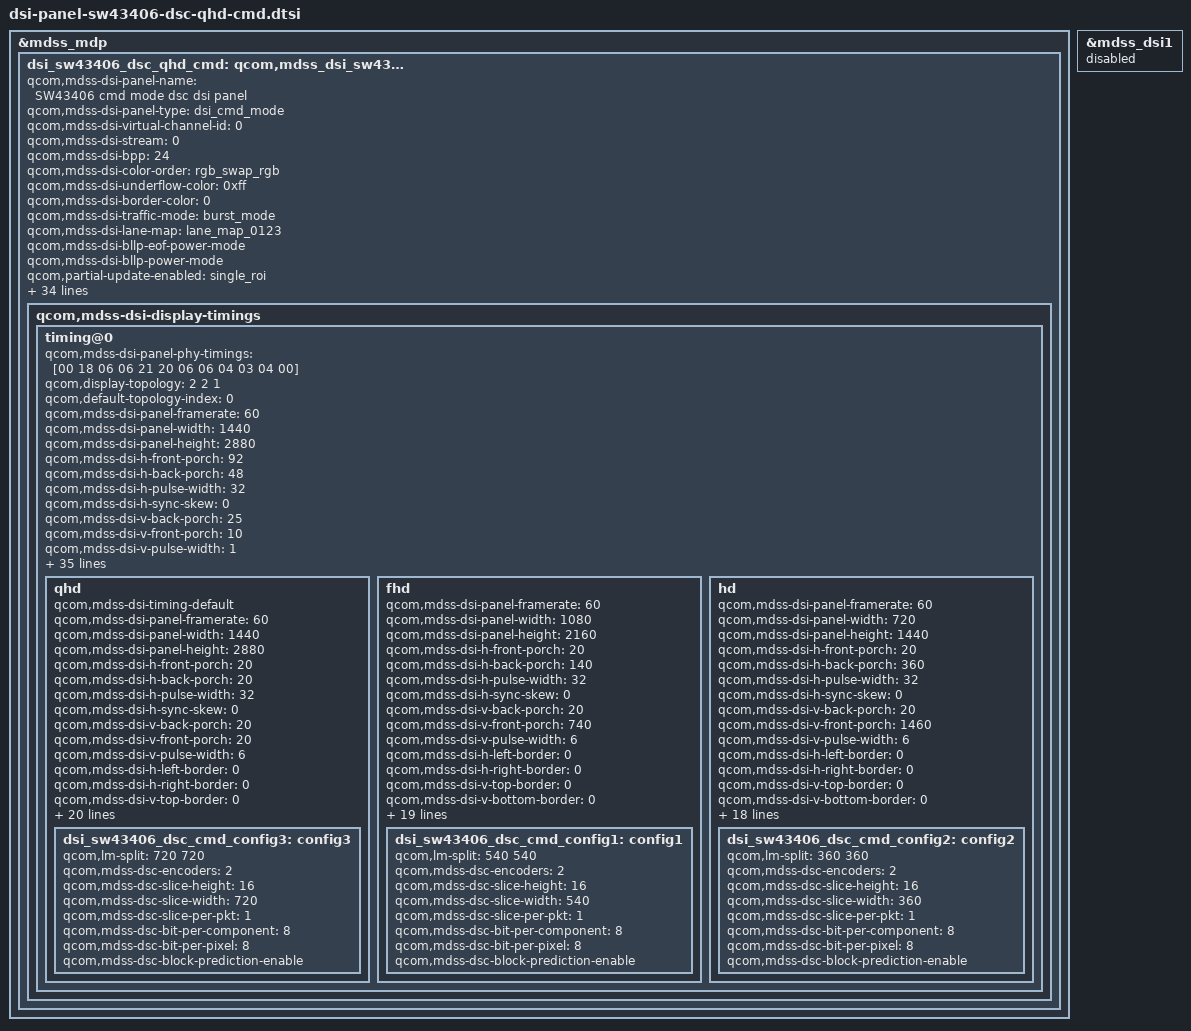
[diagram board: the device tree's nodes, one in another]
/* Copyright (c) 2014, Code Aurora Forum. All rights reserved.
 *
 * This program is free software; you can redistribute it and/or modify
 * it under the terms of the GNU General Public License version 2 and
 * only version 2 as published by the Free Software Foundation.
 *
 * This program is distributed in the hope that it will be useful,
 * but WITHOUT ANY WARRANTY; without even the implied warranty of
 * MERCHANTABILITY or FITNESS FOR A PARTICULAR PURPOSE.  See the
 * GNU General Public License for more details.
 */

//#include "dsi-panel-sw43406-dynamic-resolution-switching.dtsi"

&mdss_mdp {
    dsi_sw43406_dsc_qhd_cmd: qcom,mdss_dsi_sw43406_dsc_qhd_cmd {
        qcom,mdss-dsi-panel-name = "SW43406 cmd mode dsc dsi panel";
		qcom,mdss-dsi-panel-type = "dsi_cmd_mode";

		qcom,mdss-dsi-virtual-channel-id = <0>;
		qcom,mdss-dsi-stream = <0>;
		qcom,mdss-dsi-bpp = <24>;
		qcom,mdss-dsi-color-order = "rgb_swap_rgb";
		qcom,mdss-dsi-underflow-color = <0xff>;
		qcom,mdss-dsi-border-color = <0>;
		//qcom,esd-check-enabled;
		//qcom,mdss-dsi-panel-status-check-mode = "te_signal_check";
		qcom,mdss-dsi-traffic-mode = "burst_mode";
		qcom,mdss-dsi-lane-map = "lane_map_0123";
		qcom,mdss-dsi-bllp-eof-power-mode;
		qcom,mdss-dsi-bllp-power-mode;
		qcom,partial-update-enabled = "single_roi";
		qcom,panel-roi-alignment = <1440 16 1440 16 1440 16>;
		qcom,mdss-dsi-lane-0-state;
		qcom,mdss-dsi-lane-1-state;
		qcom,mdss-dsi-lane-2-state;
		qcom,mdss-dsi-lane-3-state;
		qcom,mdss-dsi-reset-sequence = <1 10>, <0 2>, <1 10>;
		qcom,mdss-dsi-dma-trigger = "trigger_sw";
		qcom,mdss-dsi-mdp-trigger = "none";
		qcom,mdss-dsi-te-pin-select = <1>;
		qcom,mdss-dsi-wr-mem-start = <0x2c>;
		qcom,mdss-dsi-wr-mem-continue = <0x3c>;
		qcom,mdss-dsi-te-dcs-command = <1>;
		qcom,mdss-dsi-te-check-enable;
		qcom,mdss-dsi-te-using-te-pin;
		qcom,mdss-dsi-lp11-init;
//		qcom,mdss-dsi-tx-eot-append;
		qcom,mdss-mdp-transfer-time-us = <15000>;
//		qcom,ulps-enabled;
		qcom,mdss-dsi-force-clock-lane-hs = <1>;

		qcom,mdss-dsi-panel-hdr-enabled;
		qcom,mdss-dsi-panel-hdr-color-primaries = <14880 15935 32435 16555 14945 30910 7790 3415>;
		qcom,mdss-dsi-panel-peak-brightness = <5643000>;		/* max. 500nits */
		qcom,mdss-dsi-panel-blackness-level = <6134>;
		qcom,dynamic-mode-switch-enabled;
		qcom,dynamic-mode-switch-type = "dynamic-resolution-switch-immediate";

		lge,blmap = <
			3
			30 30 30 30 30 30 30 30 30 30 30 30 30 30 30 30 30 30 31 33
			35 35 36 37 38 39 39 40 41 41 42 42 42 43 44 45 45 45 45 45
			46 47 48 48 48 48 48 49 49 50 51 51 51 51 52 53 53 54 55 55
			55 55 56 56 57 57 57 58 59 60 60 60 61 61 62 62 63 64 65 66
			67 68 69 69 70 71 73 73 74 75 76 77 78 79 80 81 82 82 83 84
			85 86 87 88 89 90 91 92 92 92 93 94 96 98 98 99 100 102 104 105
			106 107 108 109 110 111 112 113 114 114 114 115 116 117 118 120 120 120 121 122
			123 123 123 124 124 125 126 127 128 128 129 130 131 132 133 134 135 135 135 136
			137 138 139 139 140 141 142 143 143 143 144 145 146 147 148 149 150 151 152 153
			153 153 154 155 156 156 157 158 159 160 160 161 162 162 163 164 165 166 167 169
			169 171 173 175 177 179 179 179 180 181 183 185 185 186 187 188 190 191 192 193
			195 196 197 198 199 200 201 202 203 205 206 208 209 210 211 212 213 214 215 216
			217 218 219 221 222 224 226 227 229 230 232 234 236 238 239 239 239 239 239 239
			239 239 239 239 239 239 239 240 240 240 240 240 240 240 240 240 240 240 240 240
			240 240 240 240 240 240 240 240 240 240 240 240 240 240 240 240 241 241 241 241
			241 241 241 241 241 241 241 241 241 241 241 241 242 242 242 242 242 242 242 242
			242 242 242 242 242 242 243 243 243 243 243 243 243 243 243 244 244 244 244 245
			245 245 245 246 246 246 246 246 247 247 247 247 248 248 248 248 249 249 249 249
			250 250 250 250 251 251 251 251 251 251 251 251 251 251 251 251 251 251 251 251
			251 251 251 251 251 251 251 251 251 251 251 251 251 251 251 251 251 251 251 251
			251 251 251 251 251 251 251 251 251 251 251 251 251 251 251 251 251 251 251 251
			251 251 251 251 251 251 251 251 251 251 251 251 251 251 251 251 251 251 251 251
			251 251 251 251 251 251 251 251 251 251 251 251 251 251 251 251 251 251 251 251
			251 251 251 251 251 251 251 251 251 251 251 251 251 251 251 251 251 251 251 251
			251 251 251 251 251 251 251 251 251 251 251 251 251 251 251 251 251 251 251 251
			251 251 251 251 251 251 251 251 251 251 251
		>;

		lge,blmap-ex = <
			3
			41 41 41 41 41 41 41 41 41 41 41 41 41 41 41 42 42 42 43 43
			44 44 45 46 47 49 49 49 50 51 53 54 55 56 58 60 61 63 64 65
			67 68 70 71 72 74 76 78 79 81 83 84 86 87 89 91 93 95 97 99
			100 101 103 104 106 107 108 110 113 116 117 119 121 123 125 126 127 129 131 134
			135 136 138 140 142 144 146 147 148 150 152 155 157 159 162 164 166 167 169 171
			173 176 177 178 179 181 183 185 187 189	191 193 195 198 200 202 204 206 209 210
			212 214 216 219 220 222 224 226 228 230	232 234 236 238 240 243 244 245 246 249
			252 252 253 254 254 255 255 255 255 255	255 255 255 255 255 255 255 255 255 255
			255 255 255 255 255 255 255 255 255 255	255 255 255 255 255 255 255 255 255 255
			255 255 255 255 255 255 255 255 255 255	255 255 255 255 255 255 255 255 255 255
			255 255 255 255 255 255 255 255 255 255	255 255 255 255 255 255 255 255 255 255
			255 255 255 255 255 255 255 255 255 255	255 255 255 255 255 255 255 255 255 255
			255 255 255 255 255 255 255 255 255 255	255 255 255 255 255 255 255 255 255 255
			255 255 255 255 255 255 255 255 255 255	255 255 255 255 255 255 255 255 255 255
			255 255 255 255 255 255 255 255 255 255	255 255 255 255 255 255 255 255 255 255
			255 255 255 255 255 255 255 255 255 255	255 255 255 255 255 255 255 255 255 255
			255 255 255 255 255 255 255 255 255 255	255 255 255 255 255 255 255 255 255 255
			255 255 255 255 255 255 255 255 255 255	255 255 255 255 255 255 255 255 255 255
			255 255 255 255 255 255 255 255 255 255	255 255 255 255 255 255 255 255 255 255
			255 255 255 255 255 255 255 255 255 255	255 255 255 255 255 255 255 255 255 255
			255 255 255 255 255 255 255 255 255 255	255 255 255 255 255 255 255 255 255 255
			255 255 255 255 255 255 255 255 255 255	255 255 255 255 255 255 255 255 255 255
			255 255 255 255 255 255 255 255 255 255	255 255 255 255 255 255 255 255 255 255
			255 255 255 255 255 255 255 255 255 255	255 255 255 255 255 255 255 255 255 255
			255 255 255 255 255 255 255 255 255 255	255 255 255 255 255 255 255 255 255 255
			255 255 255 255 255 255 255 255 255 255	255
		>;

		qcom,mdss-pan-physical-width-dimension = <68>;
		qcom,mdss-pan-physical-height-dimension = <136>;

		qcom,mdss-dsi-t-clk-post = <0x0C>;
		qcom,mdss-dsi-t-clk-pre = <0x27>;

		qcom,mdss-dsi-display-timings {
			timing@0{
				qcom,mdss-dsi-panel-phy-timings = [00 18 06 06 21 20 06 06 04 03 04 00];
				qcom,display-topology = <2 2 1>;
				qcom,default-topology-index = <0>;
				qcom,mdss-dsi-panel-framerate = <60>;
				qcom,mdss-dsi-panel-width = <1440>;
				qcom,mdss-dsi-panel-height = <2880>;
				qcom,mdss-dsi-h-front-porch = <92>;
				qcom,mdss-dsi-h-back-porch = <48>;
				qcom,mdss-dsi-h-pulse-width = <32>;
				qcom,mdss-dsi-h-sync-skew = <0>;
				qcom,mdss-dsi-v-back-porch = <25>;
				qcom,mdss-dsi-v-front-porch = <10>;
				qcom,mdss-dsi-v-pulse-width = <1>;
				qcom,mdss-dsi-h-left-border = <0>;
				qcom,mdss-dsi-h-right-border = <0>;
				qcom,mdss-dsi-v-top-border = <0>;
				qcom,mdss-dsi-v-bottom-border = <0>;
				qcom,mdss-dsi-on-command = [
					39 01 00 00 00 00 03 B0 60 43
					15 01 00 00 00 00 02 3D 00
					39 01 00 00 00 00 03 DF 0B 00
					15 01 00 00 00 00 02 F2 00
					39 01 00 00 01 00 03 FF 03 00
					05 01 00 00 14 00 01 35
					05 01 00 00 14 00 01 11
					15 01 00 00 00 00 02 51 4F
					15 01 00 00 00 00 02 53 00
					15 01 00 00 00 00 02 55 0C
					39 01 00 00 00 00 03 B0 A5 00
					39 01 00 00 00 00 16 D4 10 00 FF A8 80 54 80 20 20 20 20 56 00 56 00 56 00 15 55 56 55
					39 01 00 00 00 00 1D D6 70 56 5E 40 18 18 F0 C8 88 88 DC 00 10 06 10 30 78 78 78 6C 74 5C 34 52 64 60 58 5C
					39 01 00 00 00 00 1D D7 70 5A 58 48 38 08 D8 E8 06 F8 F8 E8 A4 D8 28 3E 7C 74 6C 64 68 60 64 64 74 50 48 5A
					39 01 00 00 00 00 1D D8 70 48 50 38 30 14 F0 C8 84 82 C0 1C 14 00 00 3A 6A 62 54 50 58 4C 28 44 62 5A 48 52
					39 01 00 00 00 00 1D D9 70 5A 5E 40 30 08 F4 F8 00 EC F0 FD 14 06 3C 3A 6A 64 5C 5C 62 62 50 56 60 52 50 56
					39 01 00 00 00 00 03 FB 03 77
					39 01 00 00 14 00 06 ED 13 00 07 00 31
					39 01 00 00 3C 00 03 B0 A5 00
					];
				qcom,mdss-dsi-on-command-state = "dsi_lp_mode";

				qcom,mdss-dsi-post-panel-on-command = [
					39 01 00 00 3C 00 03 B0 A5 00
					39 01 00 00 00 00 03 B2 5D 01
					05 01 00 00 00 00 01 29
					];

				qcom,mdss-dsi-off-command = [
					39 01 00 00 00 00 05 E8 08 98 18 05
					05 01 00 00 00 00 01 28
					05 01 00 00 96 00 01 10
					];
				qcom,mdss-dsi-off-command-state = "dsi_lp_mode";

				/* lge,mode-change-cmds-doze-suspend-to-panel-on-low-power  */
				lge,mdss-change-cmds-doze-suspend-to-panel-on-low-power = [
					39 01 00 00 00 00 08 CA 00 46 00 46 00 16 11
					39 01 00 00 00 00 1F CB 02 D8 00 02 D8 00 02 D8 00 02 D8 00 02 D8 00 02 D8 00 02 D8 00 02 D8 00 02 D8 00 02 D8 00
					39 01 00 00 00 00 13 CC 02 D8 00 02 D8 00 02 D8 00 0B 5E 00 0B 5E 00 55 12 13
					39 01 00 00 28 00 0F E2 20 0D 08 A8 0A AA 04 A4 80 80 80 5C 5C 5C
					05 01 00 00 00 00 01 34
					05 01 00 00 00 00 01 38
					15 01 00 00 00 00 02 31 00
					15 01 00 00 00 00 02 51 03
					15 01 00 00 00 00 02 5E 00
					05 01 00 00 55 00 01 13
					05 01 00 00 00 00 01 35
					39 01 00 00 00 00 08 CA 00 46 00 46 00 16 11
					39 01 00 00 00 00 1F CB 20 01 CC 20 01 CC 20 01 CC 11 23 AB 11 23 AB 01 D9 F5 01 D9 F5 02 79 55 02 79 55 02 B3 1A
					39 01 00 00 00 00 13 CC 20 01 CC 20 6D 60 11 23 AB 29 18 1E 29 18 1E 55 12 13
				];
				/* lge,mode-change-cmds-panel-on-to-doze-suspend-low-power */
				lge,mdss-change-cmds-panel-on-to-doze-suspend-low-power = [
					39 01 00 00 00 00 03 B0 A5 00
					39 01 00 00 00 00 0A D2 1A BC 02 BC 01 00 06 FF 00
					39 01 00 00 00 00 08 CA 00 46 00 46 00 16 11
					39 01 00 00 00 00 1F CB 02 D8 00 02 D8 00 02 D8 00 02 D8 00 02 D8 00 02 D8 00 02 D8 00 02 D8 00 02 D8 00 02 D8 00
					39 01 00 00 00 00 13 CC 02 D8 00 02 D8 00 02 D8 00 0B 5E 00 0B 5E 00 55 12 13
					39 01 00 00 00 00 09 E5 04 04 03 03 56 21 33 0A
					39 01 00 00 00 00 13 E7 00 0D 76 1A 00 00 0D 44 0D 76 0D 0D 00 0D 0D 0D 4A 00
					39 01 00 00 46 00 0F E2 20 03 08 A8 0A AA 04 A4 80 80 80 5C 5C 5C
					05 01 00 00 00 00 01 34
					39 01 00 00 00 00 05 30 00 00 0B 3F
					15 01 00 00 00 00 02 31 00
					15 01 00 00 00 00 02 5E 00
					05 01 00 00 00 00 01 12
					39 01 00 00 00 00 0B E0 18 10 11 00 00 20 00 00 20 20
					05 01 00 00 55 00 01 39
					05 01 00 00 00 00 01 35
					39 01 00 00 00 00 08 CA 00 46 00 46 00 16 11
					39 01 00 00 00 00 1F CB 20 01 CC 20 01 CC 20 01 CC 11 23 AB 11 23 AB 01 D9 F5 01 D9 F5 02 79 55 02 79 55 02 B3 1A
					39 01 00 00 00 00 13 CC 20 01 CC 20 6D 60 11 23 AB 29 18 1E 29 18 1E 55 12 13
				];
				lge,mdss-change-cmds-doze-suspend-to-panel-on-state = "dsi_lp_mode";
				lge,mdss-change-cmds-panel-on-to-doze-suspend-state = "dsi_lp_mode";

				lge,mdss-ddvdh-default-command = [
					/* Positive Gamma Curve for Red */
					39 01 00 00 00 00 0E D0 00 10 20 2F 3B 43 4E 44 37 28 17 06 03
					/* Negative Gamma Curve for Red */
					39 01 00 00 00 00 0E D1 00 10 20 2B 38 41 4C 44 37 28 17 00 03
				];

				lge,mdss-ddvdh-tuning-command = [
					/* Positive Gamma Curve for Red */
					39 01 00 00 00 00 0E D0 00 30 40 48 4F 55 3B 31 24 17 08 00 03
					/* Negative Gamma Curve for Red */
					39 01 00 00 00 00 0E D1 00 30 40 48 4F 55 3B 31 24 17 08 00 03
				];
				lge,mdss-ddvdh-default-state = "dsi_lp_mode";
				lge,mdss-ddvdh-tuning-state = "dsi_lp_mode";
				qcom,mode-control-dsi-state = "dsi_lp_mode";

				qcom,mdss-dsi-h-sync-pulse = <0>;
				qcom,compression-mode = "dsc";
				qcom,mdss-dsc-slice-height = <16>;
				qcom,mdss-dsc-slice-width = <720>;
				qcom,mdss-dsc-slice-per-pkt = <2>;
				qcom,mdss-dsc-bit-per-component = <8>;
				qcom,mdss-dsc-bit-per-pixel = <8>;
				qcom,mdss-dsc-block-prediction-enable;

				qhd {
					qcom,mdss-dsi-timing-default;
					qcom,mdss-dsi-panel-framerate = <60>;
					qcom,mdss-dsi-panel-width = <1440>;
					qcom,mdss-dsi-panel-height = <2880>;
					qcom,mdss-dsi-h-front-porch = <20>;
					qcom,mdss-dsi-h-back-porch = <20>;
					qcom,mdss-dsi-h-pulse-width = <32>;
					qcom,mdss-dsi-h-sync-skew = <0>;
					qcom,mdss-dsi-v-back-porch = <20>;
					qcom,mdss-dsi-v-front-porch = <20>;
					qcom,mdss-dsi-v-pulse-width = <6>;
					qcom,mdss-dsi-h-left-border = <0>;
					qcom,mdss-dsi-h-right-border = <0>;
					qcom,mdss-dsi-v-top-border = <0>;
					qcom,mdss-dsi-v-bottom-border = <0>;
					qcom,mdss-dsi-panel-timings = [00 14 05 05 08 0E 04 05 04 03 04 00];
					qcom,mdss-dsi-t-clk-post = <0x06>;
					qcom,mdss-dsi-t-clk-pre = <0x20>;

					qcom,mdss-dsi-on-command = [
						39 01 00 00 00 00 03 B0 20 43
						39 01 00 00 00 00 02 3D 00
						39 01 00 00 00 00 03 DF 0B 00
						39 01 00 00 00 00 02 F2 00
						39 01 00 00 00 00 03 FF 03 00
						05 01 00 00 78 00 01 11
						05 01 00 00 00 00 01 29
						39 01 00 00 01 00 03 B0 A5 43
						];
					qcom,mdss-dsi-on-command-state = "dsi_lp_mode";
					qcom,mdss-dsi-off-command = [
						05 01 00 00 00 00 01 28
						05 01 00 00 5A 00 01 10
						];
					qcom,mdss-dsi-timing-switch-command = [
						15 01 00 00 00 00 03 B0 20 43
						39 01 00 00 00 00 02 3D 00
						];
					qcom,mdss-dsi-timing-switch-command-state = "dsi_lp_mode";

					qcom,mdss-dsi-off-command-state = "dsi_lp_mode";
					qcom,compression-mode = "dsc";
					qcom,config-select = <&dsi_sw43406_dsc_cmd_config3>;
					qcom,mdss-dsc-version = <0x11>;
					qcom,mdss-dsc-scr-version = <0x1>;

					dsi_sw43406_dsc_cmd_config3: config3 {
				     		qcom,lm-split = <720 720>;
				     		qcom,mdss-dsc-encoders = <2>;
				     		qcom,mdss-dsc-slice-height = <16>;
				     		qcom,mdss-dsc-slice-width = <720>;
				     		qcom,mdss-dsc-slice-per-pkt = <1>;

						qcom,mdss-dsc-bit-per-component = <8>;
						qcom,mdss-dsc-bit-per-pixel = <8>;
						qcom,mdss-dsc-block-prediction-enable;
					};
				};

				fhd {
					qcom,mdss-dsi-panel-framerate = <60>;
					qcom,mdss-dsi-panel-width = <1080>;
					qcom,mdss-dsi-panel-height = <2160>;
					qcom,mdss-dsi-h-front-porch = <20>;
					qcom,mdss-dsi-h-back-porch = <140>;
					qcom,mdss-dsi-h-pulse-width = <32>;
					qcom,mdss-dsi-h-sync-skew = <0>;
					qcom,mdss-dsi-v-back-porch = <20>;
					qcom,mdss-dsi-v-front-porch = <740>;
					qcom,mdss-dsi-v-pulse-width = <6>;
					qcom,mdss-dsi-h-left-border = <0>;
					qcom,mdss-dsi-h-right-border = <0>;
					qcom,mdss-dsi-v-top-border = <0>;
					qcom,mdss-dsi-v-bottom-border = <0>;
					qcom,mdss-dsi-panel-timings = [00 14 05 05 08 0E 04 05 04 03 04 00];
					qcom,mdss-dsi-t-clk-post = <0x06>;
					qcom,mdss-dsi-t-clk-pre = <0x20>;

					qcom,mdss-dsi-on-command = [
						39 01 00 00 00 00 03 B0 20 43
						39 01 00 00 00 00 02 3D 01
						39 01 00 00 00 00 03 DF 0B 00
						39 01 00 00 00 00 02 F2 00
						39 01 00 00 00 00 03 FF 03 00
						05 01 00 00 78 00 01 11
						05 01 00 00 00 00 01 29
						39 01 00 00 01 00 03 B0 A5 43
						];
					qcom,mdss-dsi-on-command-state = "dsi_lp_mode";
					qcom,mdss-dsi-off-command = [
						05 01 00 00 00 00 01 28
						05 01 00 00 5A 00 01 10
						];
					qcom,mdss-dsi-timing-switch-command = [
						15 01 00 00 00 00 03 B0 20 43
						39 01 00 00 00 00 02 3D 01
						];
					qcom,mdss-dsi-timing-switch-command-state = "dsi_lp_mode";

					qcom,mdss-dsi-off-command-state = "dsi_lp_mode";
					qcom,compression-mode = "dsc";
					qcom,config-select = <&dsi_sw43406_dsc_cmd_config1>;
					qcom,mdss-dsc-version = <0x11>;
					qcom,mdss-dsc-scr-version = <0x1>;
					dsi_sw43406_dsc_cmd_config1: config1 {
				     		qcom,lm-split = <540 540>;

				     		qcom,mdss-dsc-encoders = <2>;
				     		qcom,mdss-dsc-slice-height = <16>;
				     		qcom,mdss-dsc-slice-width = <540>;
				     		qcom,mdss-dsc-slice-per-pkt = <1>;

				     		qcom,mdss-dsc-bit-per-component = <8>;
				     		qcom,mdss-dsc-bit-per-pixel = <8>;
				     		qcom,mdss-dsc-block-prediction-enable;
					};
				};

				hd {
					qcom,mdss-dsi-panel-framerate = <60>;
					qcom,mdss-dsi-panel-width = <720>;
					qcom,mdss-dsi-panel-height = <1440>;
					qcom,mdss-dsi-h-front-porch = <20>;
					qcom,mdss-dsi-h-back-porch = <360>;
					qcom,mdss-dsi-h-pulse-width = <32>;
					qcom,mdss-dsi-h-sync-skew = <0>;
					qcom,mdss-dsi-v-back-porch = <20>;
					qcom,mdss-dsi-v-front-porch = <1460>;
					qcom,mdss-dsi-v-pulse-width = <6>;
					qcom,mdss-dsi-h-left-border = <0>;
					qcom,mdss-dsi-h-right-border = <0>;
					qcom,mdss-dsi-v-top-border = <0>;
					qcom,mdss-dsi-v-bottom-border = <0>;
					qcom,mdss-dsi-panel-timings = [00 14 05 05 08 0E 04 05 04 03 04 00];
					qcom,mdss-dsi-t-clk-post = <0x06>;
					qcom,mdss-dsi-t-clk-pre = <0x20>;

					qcom,mdss-dsi-on-command = [
						39 01 00 00 00 00 03 B0 20 43
						39 01 00 00 00 00 02 3D 03
						39 01 00 00 00 00 03 DF 0B 00
						39 01 00 00 00 00 02 F2 00
						39 01 00 00 00 00 03 FF 03 00
						05 01 00 00 78 00 01 11
						05 01 00 00 00 00 01 29
						39 01 00 00 01 00 03 B0 A5 43
						];
					qcom,mdss-dsi-on-command-state = "dsi_lp_mode";
					qcom,mdss-dsi-off-command = [
						05 01 00 00 00 00 01 28
						05 01 00 00 5A 00 01 10
						];
					qcom,mdss-dsi-timing-switch-command = [
						15 01 00 00 00 00 03 B0 20 43
						39 01 00 00 00 00 02 3D 03
						];
					qcom,mdss-dsi-timing-switch-command-state = "dsi_lp_mode";

					qcom,compression-mode = "dsc";
					qcom,config-select = <&dsi_sw43406_dsc_cmd_config2>;
					qcom,mdss-dsc-version = <0x11>;
					qcom,mdss-dsc-scr-version = <0x1>;

					dsi_sw43406_dsc_cmd_config2: config2 {
				     		qcom,lm-split = <360 360>;
				     		qcom,mdss-dsc-encoders = <2>;
				     		qcom,mdss-dsc-slice-height = <16>;
				     		qcom,mdss-dsc-slice-width = <360>;
				     		qcom,mdss-dsc-slice-per-pkt = <1>;

				     		qcom,mdss-dsc-bit-per-component = <8>;
				     		qcom,mdss-dsc-bit-per-pixel = <8>;
				     		qcom,mdss-dsc-block-prediction-enable;
					};
				};
			};
		};
	};
};
/*
&spmi_bus {
	qcom,pmi8998@3 {
		labibb: qpnp-labibb-regulator {
			status = "disabled";
		};
	};
};
*/
&mdss_dsi1 {
	status = "disabled";
};
